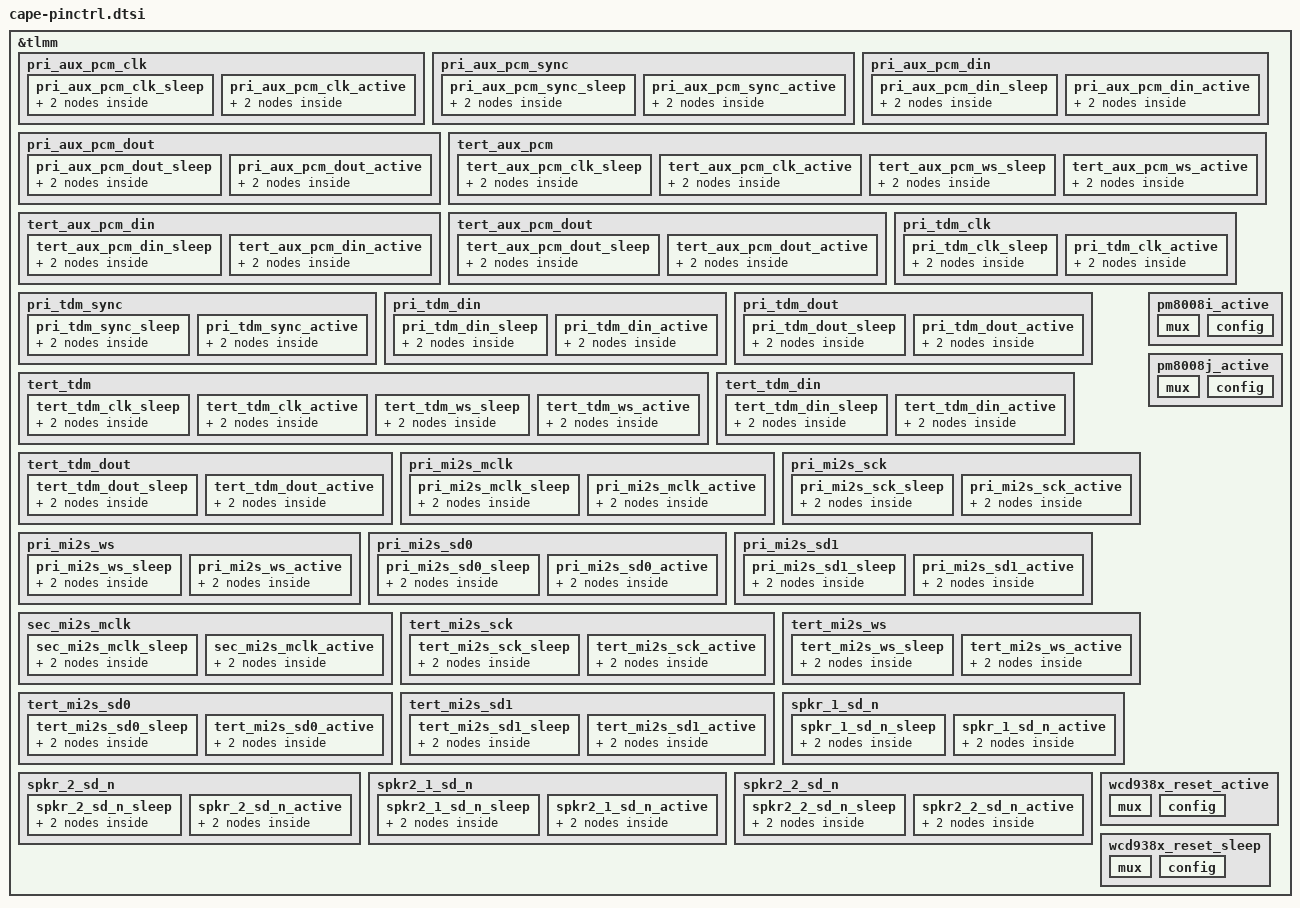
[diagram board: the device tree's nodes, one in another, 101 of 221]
&tlmm {
	pri_aux_pcm_clk {
		pri_aux_pcm_clk_sleep: pri_aux_pcm_clk_sleep {
			mux {
				pins = "gpio126";
				function = "gpio";
			};

			config {
				pins = "gpio126";
				drive-strength = <2>;   /* 2 mA */
				bias-pull-down;         /* PULL DOWN */
				input-enable;
			};
		};

		pri_aux_pcm_clk_active: pri_aux_pcm_clk_active {
			mux {
				pins = "gpio126";
				function = "mi2s0_sck";
			};

			config {
				pins = "gpio126";
				drive-strength = <8>;   /* 8 mA */
				bias-disable;           /* NO PULL */
				output-high;
			};
		};
	};

	pri_aux_pcm_sync {
		pri_aux_pcm_sync_sleep: pri_aux_pcm_sync_sleep {
			mux {
				pins = "gpio129";
				function = "gpio";
			};

			config {
				pins = "gpio129";
				drive-strength = <2>;   /* 2 mA */
				bias-pull-down;         /* PULL DOWN */
				input-enable;
			};
		};

		pri_aux_pcm_sync_active: pri_aux_pcm_sync_active {
			mux {
				pins = "gpio129";
				function = "mi2s0_ws";
			};

			config {
				pins = "gpio129";
				drive-strength = <8>;   /* 8 mA */
				bias-disable;           /* NO PULL */
				output-high;
			};
		};
	};

	pri_aux_pcm_din {
		pri_aux_pcm_din_sleep: pri_aux_pcm_din_sleep {
			mux {
				pins = "gpio127";
				function = "gpio";
			};

			config {
				pins = "gpio127";
				drive-strength = <2>;   /* 2 mA */
				bias-pull-down;         /* PULL DOWN */
				input-enable;
			};
		};

		pri_aux_pcm_din_active: pri_aux_pcm_din_active {
			mux {
				pins = "gpio127";
				function = "mi2s0_data0";
			};

			config {
				pins = "gpio127";
				drive-strength = <8>;   /* 8 mA */
				bias-disable;           /* NO PULL */
			};
		};
	};

	pri_aux_pcm_dout {
		pri_aux_pcm_dout_sleep: pri_aux_pcm_dout_sleep {
			mux {
				pins = "gpio128";
				function = "gpio";
			};

			config {
				pins = "gpio128";
				drive-strength = <2>;   /* 2 mA */
				bias-pull-down;         /* PULL DOWN */
				input-enable;
			};
		};

		pri_aux_pcm_dout_active: pri_aux_pcm_dout_active {
			mux {
				pins = "gpio128";
				function = "mi2s0_data1";
			};

			config {
				pins = "gpio128";
				drive-strength = <8>;   /* 8 mA */
				bias-disable;           /* NO PULL */
			};
		};
	};

	tert_aux_pcm {
		tert_aux_pcm_clk_sleep: tert_aux_pcm_clk_sleep {
			mux {
				pins = "gpio121";
				function = "gpio";
			};

			config {
				pins = "gpio121";
				drive-strength = <2>;   /* 2 mA */
				bias-pull-down;         /* PULL DOWN */
				input-enable;
			};
		};

		tert_aux_pcm_clk_active: tert_aux_pcm_clk_active {
			mux {
				pins = "gpio121";
				function = "mi2s2_sck";
			};

			config {
				pins = "gpio121";
				drive-strength = <8>;   /* 8 mA */
				bias-disable;           /* NO PULL */
				output-high;
			};
		};

		tert_aux_pcm_ws_sleep: tert_aux_pcm_ws_sleep {
			mux {
				pins = "gpio123";
				function = "gpio";
			};

			config {
				pins = "gpio123";
				drive-strength = <2>;   /* 2 mA */
				bias-pull-down;         /* PULL DOWN */
				input-enable;
			};
		};

		tert_aux_pcm_ws_active: tert_aux_pcm_ws_active {
			mux {
				pins = "gpio123";
				function = "mi2s2_ws";
			};

			config {
				pins = "gpio123";
				drive-strength = <8>;   /* 8 mA */
				bias-disable;           /* NO PULL */
				output-high;
			};
		};
	};

	tert_aux_pcm_din {
		tert_aux_pcm_din_sleep: tert_aux_pcm_din_sleep {
			mux {
				pins = "gpio122";
				function = "gpio";
			};

			config {
				pins = "gpio122";
				drive-strength = <2>;   /* 2 mA */
				bias-pull-down;         /* PULL DOWN */
				input-enable;
			};
		};

		tert_aux_pcm_din_active: tert_aux_pcm_din_active {
			mux {
				pins = "gpio122";
				function = "mi2s2_data0";
			};

			config {
				pins = "gpio122";
				drive-strength = <8>;   /* 8 mA */
				bias-disable;           /* NO PULL */
			};
		};
	};

	tert_aux_pcm_dout {
		tert_aux_pcm_dout_sleep: tert_aux_pcm_dout_sleep {
			mux {
				pins = "gpio124";
				function = "gpio";
			};

			config {
				pins = "gpio124";
				drive-strength = <2>;   /* 2 mA */
				bias-pull-down;         /* PULL DOWN */
				input-enable;
			};
		};

		tert_aux_pcm_dout_active: tert_aux_pcm_dout_active {
			mux {
				pins = "gpio124";
				function = "mi2s2_data1";
			};

			config {
				pins = "gpio124";
				drive-strength = <8>;   /* 8 mA */
				bias-disable;           /* NO PULL */
			};
		};
	};

	pri_tdm_clk {
		pri_tdm_clk_sleep: pri_tdm_clk_sleep {
			mux {
				pins = "gpio126";
				function = "gpio";
			};

			config {
				pins = "gpio126";
				drive-strength = <2>;   /* 2 mA */
				bias-pull-down;         /* PULL DOWN */
				input-enable;
			};
		};

		pri_tdm_clk_active: pri_tdm_clk_active {
			mux {
				pins = "gpio126";
				function = "mi2s0_sck";
			};

			config {
				pins = "gpio126";
				drive-strength = <8>;   /* 8 mA */
				bias-disable;           /* NO PULL */
				output-high;
			};
		};
	};

	pri_tdm_sync {
		pri_tdm_sync_sleep: pri_tdm_sync_sleep {
			mux {
				pins = "gpio129";
				function = "gpio";
			};

			config {
				pins = "gpio129";
				drive-strength = <2>;   /* 2 mA */
				bias-pull-down;         /* PULL DOWN */
				input-enable;
			};
		};

		pri_tdm_sync_active: pri_tdm_sync_active {
			mux {
				pins = "gpio129";
				function = "mi2s0_ws";
			};

			config {
				pins = "gpio129";
				drive-strength = <8>;   /* 8 mA */
				bias-disable;           /* NO PULL */
				output-high;
			};
		};
	};

	pri_tdm_din {
		pri_tdm_din_sleep: pri_tdm_din_sleep {
			mux {
				pins = "gpio127";
				function = "gpio";
			};

			config {
				pins = "gpio127";
				drive-strength = <2>;   /* 2 mA */
				bias-pull-down;         /* PULL DOWN */
				input-enable;
			};
		};

		pri_tdm_din_active: pri_tdm_din_active {
			mux {
				pins = "gpio127";
				function = "mi2s0_data0";
			};

			config {
				pins = "gpio127";
				drive-strength = <8>;   /* 8 mA */
				bias-disable;           /* NO PULL */
			};
		};
	};

	pri_tdm_dout {
		pri_tdm_dout_sleep: pri_tdm_dout_sleep {
			mux {
				pins = "gpio128";
				function = "gpio";
			};

			config {
				pins = "gpio128";
				drive-strength = <2>;   /* 2 mA */
				bias-pull-down;         /* PULL DOWN */
				input-enable;
			};
		};

		pri_tdm_dout_active: pri_tdm_dout_active {
			mux {
				pins = "gpio128";
				function = "mi2s0_data1";
			};

			config {
				pins = "gpio128";
				drive-strength = <8>;   /* 8 mA */
				bias-disable;           /* NO PULL */
			};
		};
	};

	tert_tdm {
		tert_tdm_clk_sleep: tert_tdm_clk_sleep {
			mux {
				pins = "gpio121";
				function = "gpio";
			};

			config {
				pins = "gpio121";
				drive-strength = <2>;   /* 2 mA */
				bias-pull-down;         /* PULL DOWN */
				input-enable;
			};
		};

		tert_tdm_clk_active: tert_tdm_clk_active {
			mux {
				pins = "gpio121";
				function = "mi2s2_sck";
			};

			config {
				pins = "gpio121";
				drive-strength = <8>;   /* 8 mA */
				bias-disable;           /* NO PULL */
				output-high;
			};
		};

		tert_tdm_ws_sleep: tert_tdm_ws_sleep {
			mux {
				pins = "gpio123";
				function = "gpio";
			};

			config {
				pins = "gpio123";
				drive-strength = <2>;   /* 2 mA */
				bias-pull-down;         /* PULL DOWN */
				input-enable;
			};
		};

		tert_tdm_ws_active: tert_tdm_ws_active {
			mux {
				pins = "gpio123";
				function = "mi2s2_ws";
			};

			config {
				pins = "gpio123";
				drive-strength = <8>;   /* 8 mA */
				bias-disable;           /* NO PULL */
				output-high;
			};
		};
	};

	tert_tdm_din {
		tert_tdm_din_sleep: tert_tdm_din_sleep {
			mux {
				pins = "gpio122";
				function = "gpio";
			};

			config {
				pins = "gpio122";
				drive-strength = <2>;   /* 2 mA */
				bias-pull-down;         /* PULL DOWN */
				input-enable;
			};
		};

		tert_tdm_din_active: tert_tdm_din_active {
			mux {
				pins = "gpio122";
				function = "mi2s2_data0";
			};

			config {
				pins = "gpio122";
				drive-strength = <8>;   /* 8 mA */
				bias-disable;           /* NO PULL */
			};
		};
	};

	tert_tdm_dout {
		tert_tdm_dout_sleep: tert_tdm_dout_sleep {
			mux {
				pins = "gpio124";
				function = "gpio";
			};

			config {
				pins = "gpio124";
				drive-strength = <2>;   /* 2 mA */
				bias-pull-down;         /* PULL DOWN */
				input-enable;
			};
		};

		tert_tdm_dout_active: tert_tdm_dout_active {
			mux {
				pins = "gpio124";
				function = "mi2s2_data1";
			};

			config {
				pins = "gpio124";
				drive-strength = <8>;   /* 8 mA */
				bias-disable;           /* NO PULL */
			};
		};
	};

	pri_mi2s_mclk {
		pri_mi2s_mclk_sleep: pri_mi2s_mclk_sleep {
			mux {
				pins = "gpio125";
				function = "gpio";
			};

			config {
				pins = "gpio125";
				drive-strength = <2>;   /* 2 mA */
				bias-pull-down;         /* PULL DOWN */
				input-enable;
			};
		};

		pri_mi2s_mclk_active: pri_mi2s_mclk_active {
			mux {
				pins = "gpio125";
				function = "pri_mi2s";
			};

			config {
				pins = "gpio125";
				drive-strength = <8>;   /* 8 mA */
				bias-disable;           /* NO PULL */
				output-high;
			};
		};
	};

	pri_mi2s_sck {
		pri_mi2s_sck_sleep: pri_mi2s_sck_sleep {
			mux {
				pins = "gpio126";
				function = "gpio";
			};

			config {
				pins = "gpio126";
				drive-strength = <2>;   /* 2 mA */
				bias-pull-down;         /* PULL DOWN */
				input-enable;
			};
		};

		pri_mi2s_sck_active: pri_mi2s_sck_active {
			mux {
				pins = "gpio126";
				function = "mi2s0_sck";
			};

			config {
				pins = "gpio126";
				drive-strength = <8>;   /* 8 mA */
				bias-disable;           /* NO PULL */
				output-high;
			};
		};
	};

	pri_mi2s_ws {
		pri_mi2s_ws_sleep: pri_mi2s_ws_sleep {
			mux {
				pins = "gpio129";
				function = "gpio";
			};

			config {
				pins = "gpio129";
				drive-strength = <2>;   /* 2 mA */
				bias-pull-down;         /* PULL DOWN */
				input-enable;
			};
		};

		pri_mi2s_ws_active: pri_mi2s_ws_active {
			mux {
				pins = "gpio129";
				function = "mi2s0_ws";
			};

			config {
				pins = "gpio129";
				drive-strength = <8>;   /* 8 mA */
				bias-disable;           /* NO PULL */
				output-high;
			};
		};
	};

	pri_mi2s_sd0 {
		pri_mi2s_sd0_sleep: pri_mi2s_sd0_sleep {
			mux {
				pins = "gpio127";
				function = "gpio";
			};

			config {
				pins = "gpio127";
				drive-strength = <2>;   /* 2 mA */
				bias-pull-down;         /* PULL DOWN */
				input-enable;
			};
		};

		pri_mi2s_sd0_active: pri_mi2s_sd0_active {
			mux {
				pins = "gpio127";
				function = "mi2s0_data0";
			};

			config {
				pins = "gpio127";
				drive-strength = <8>;   /* 8 mA */
				bias-disable;           /* NO PULL */
				output-high;
			};
		};
	};

	pri_mi2s_sd1 {
		pri_mi2s_sd1_sleep: pri_mi2s_sd1_sleep {
			mux {
				pins = "gpio128";
				function = "gpio";
			};

			config {
				pins = "gpio128";
				drive-strength = <2>;   /* 2 mA */
				bias-pull-down;         /* PULL DOWN */
				input-enable;
			};
		};

		pri_mi2s_sd1_active: pri_mi2s_sd1_active {
			mux {
				pins = "gpio128";
				function = "mi2s0_data1";
			};

			config {
				pins = "gpio128";
				drive-strength = <8>;   /* 8 mA */
				bias-disable;           /* NO PULL */
				output-high;
			};
		};
	};

	sec_mi2s_mclk {
		sec_mi2s_mclk_sleep: sec_mi2s_mclk_sleep {
			mux {
				pins = "gpio124";
				function = "gpio";
			};

			config {
				pins = "gpio124";
				drive-strength = <2>;   /* 2 mA */
				bias-pull-down;         /* PULL DOWN */
				input-enable;
			};
		};

		sec_mi2s_mclk_active: sec_mi2s_mclk_active {
			mux {
				pins = "gpio124";
				function = "sec_mi2s";
			};

			config {
				pins = "gpio124";
				drive-strength = <8>;   /* 8 mA */
				bias-disable;           /* NO PULL */
				output-high;
			};
		};
	};

	tert_mi2s_sck {
		tert_mi2s_sck_sleep: tert_mi2s_sck_sleep {
			mux {
				pins = "gpio121";
				function = "gpio";
			};

			config {
				pins = "gpio121";
				drive-strength = <2>;   /* 2 mA */
				bias-pull-down;         /* PULL DOWN */
				input-enable;
			};
		};

		tert_mi2s_sck_active: tert_mi2s_sck_active {
			mux {
				pins = "gpio121";
				function = "mi2s2_sck";
			};

			config {
				pins = "gpio121";
				drive-strength = <8>;   /* 8 mA */
				bias-disable;           /* NO PULL */
			};
		};
	};

	tert_mi2s_ws {
		tert_mi2s_ws_sleep: tert_mi2s_ws_sleep {
			mux {
				pins = "gpio123";
				function = "gpio";
			};

			config {
				pins = "gpio123";
				drive-strength = <2>;   /* 2 mA */
				bias-pull-down;         /* PULL DOWN */
				input-enable;
			};
		};

		tert_mi2s_ws_active: tert_mi2s_ws_active {
			mux {
				pins = "gpio123";
				function = "mi2s2_ws";
			};

			config {
				pins = "gpio123";
				drive-strength = <8>;   /* 8 mA */
				bias-disable;           /* NO PULL */
			};
		};
	};

	tert_mi2s_sd0 {
		tert_mi2s_sd0_sleep: tert_mi2s_sd0_sleep {
			mux {
				pins = "gpio122";
				function = "gpio";
			};

			config {
				pins = "gpio122";
				drive-strength = <2>;   /* 2 mA */
				bias-pull-down;         /* PULL DOWN */
				input-enable;
			};
		};

		tert_mi2s_sd0_active: tert_mi2s_sd0_active {
			mux {
				pins = "gpio122";
				function = "mi2s2_data0";
			};

			config {
				pins = "gpio122";
				drive-strength = <8>;   /* 8 mA */
				bias-disable;           /* NO PULL */
			};
		};
	};

	tert_mi2s_sd1 {
		tert_mi2s_sd1_sleep: tert_mi2s_sd1_sleep {
			mux {
				pins = "gpio124";
				function = "gpio";
			};

			config {
				pins = "gpio124";
				drive-strength = <2>;   /* 2 mA */
				bias-pull-down;         /* PULL DOWN */
				input-enable;
			};
		};

		tert_mi2s_sd1_active: tert_mi2s_sd1_active {
			mux {
				pins = "gpio124";
				function = "mi2s2_data1";
			};

			config {
				pins = "gpio124";
				drive-strength = <8>;   /* 8 mA */
				bias-disable;           /* NO PULL */
			};
		};
	};

	pm8008i_active: pm8008i_active {
		mux {
			pins = "gpio7";
			function = "gpio";
		};

		config {
			pins = "gpio7";
			bias-disable;
			output-high;
			drive-strength = <2>;
		};
	};

	pm8008j_active: pm8008j_active {
		mux {
			pins = "gpio11";
			function = "gpio";
		};

		config {
			pins = "gpio11";
			bias-disable;
			output-high;
			drive-strength = <2>;
		};
	};

	/* WSA speaker reset pins */
	spkr_1_sd_n {
		spkr_1_sd_n_sleep: spkr_1_sd_n_sleep {
			mux {
				pins = "gpio1";
				function = "gpio";
			};

			config {
				pins = "gpio1";
				drive-strength = <2>;   /* 2 mA */
				bias-pull-down;
				input-enable;
			};
		};

		spkr_1_sd_n_active: spkr_1_sd_n_active {
			mux {
				pins = "gpio1";
				function = "gpio";
			};

			config {
				pins = "gpio1";
				drive-strength = <16>;   /* 16 mA */
				bias-disable;
				output-high;
			};
		};
	};

	spkr_2_sd_n {
		spkr_2_sd_n_sleep: spkr_2_sd_n_sleep {
			mux {
				pins = "gpio89";
				function = "gpio";
			};

			config {
				pins = "gpio89";
				drive-strength = <2>;   /* 2 mA */
				bias-pull-down;
				input-enable;
			};
		};

		spkr_2_sd_n_active: spkr_2_sd_n_active {
			mux {
				pins = "gpio89";
				function = "gpio";
			};

			config {
				pins = "gpio89";
				drive-strength = <16>;   /* 16 mA */
				bias-disable;
				output-high;
			};
		};
	};

	spkr2_1_sd_n {
		spkr2_1_sd_n_sleep: spkr2_1_sd_n_sleep {
			mux {
				pins = "gpio71";
				function = "gpio";
			};

			config {
				pins = "gpio71";
				drive-strength = <2>;   /* 2 mA */
				bias-pull-down;
				input-enable;
			};
		};

		spkr2_1_sd_n_active: spkr2_1_sd_n_active {
			mux {
				pins = "gpio71";
				function = "gpio";
			};

			config {
				pins = "gpio71";
				drive-strength = <16>;   /* 16 mA */
				bias-disable;
				output-high;
			};
		};
	};

	spkr2_2_sd_n {
		spkr2_2_sd_n_sleep: spkr2_2_sd_n_sleep {
			mux {
				pins = "gpio3";
				function = "gpio";
			};

			config {
				pins = "gpio3";
				drive-strength = <2>;   /* 2 mA */
				bias-pull-down;
				input-enable;
			};
		};

		spkr2_2_sd_n_active: spkr2_2_sd_n_active {
			mux {
				pins = "gpio3";
				function = "gpio";
			};

			config {
				pins = "gpio3";
				drive-strength = <16>;   /* 16 mA */
				bias-disable;
				output-high;
			};
		};
	};

	/* WCD reset pin */
	wcd938x_reset_active: wcd938x_reset_active {
		mux {
			pins = "gpio43";
			function = "gpio";
		};

		config {
			pins = "gpio43";
			drive-strength = <16>;
			output-high;
		};
	};

	wcd938x_reset_sleep: wcd938x_reset_sleep {
		mux {
			pins = "gpio43";
			function = "gpio";
		};

		config {
			pins = "gpio43";
			drive-strength = <16>;
			bias-disable;
			output-low;
		};
	};
};
